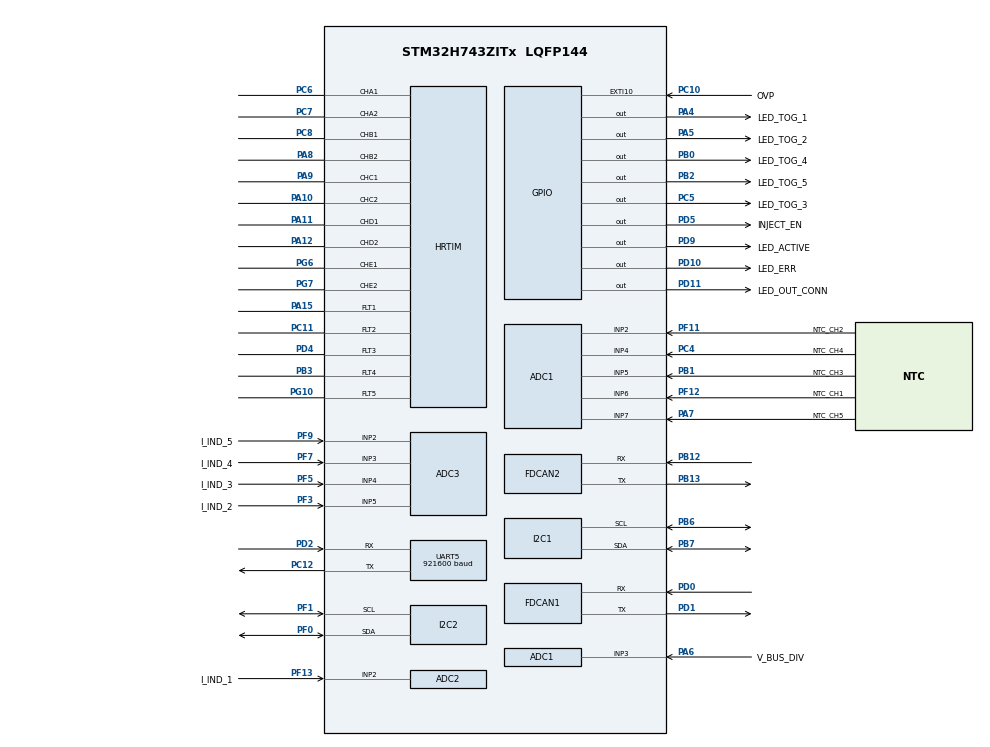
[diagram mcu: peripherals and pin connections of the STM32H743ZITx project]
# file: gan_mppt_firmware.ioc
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ADC1.Channel-0\#ChannelRegularConversion=ADC_CHANNEL_6
ADC1.ClockPrescaler=ADC_CLOCK_ASYNC_DIV4
ADC1.ClockPrescalerADC3=ADC_CLOCK_ASYNC_DIV4
ADC1.NbrOfConversionFlag=1
ADC1.OffsetNumber-0\#ChannelRegularConversion=ADC_OFFSET_NONE
ADC1.OffsetSignedSaturation-0\#ChannelRegularConversion=DISABLE
ADC1.Rank-0\#ChannelRegularConversion=1
ADC1.SamplingTime-0\#ChannelRegularConversion=ADC_SAMPLETIME_1CYCLE_5
ADC1.master=1
ADC2.Channel-0\#ChannelRegularConversion=ADC_CHANNEL_2
ADC2.ClockPrescaler=ADC_CLOCK_ASYNC_DIV4
ADC2.ClockPrescalerADC3=ADC_CLOCK_ASYNC_DIV4
ADC2.ExternalTrigConv=ADC_EXTERNALTRIG_HR1_ADCTRG1
ADC2.NbrOfConversionFlag=1
ADC2.OffsetNumber-0\#ChannelRegularConversion=ADC_OFFSET_NONE
ADC2.OffsetSignedSaturation-0\#ChannelRegularConversion=DISABLE
ADC2.Rank-0\#ChannelRegularConversion=1
ADC2.SamplingTime-0\#ChannelRegularConversion=ADC_SAMPLETIME_1CYCLE_5
ADC3.Channel-0\#ChannelRegularConversion=ADC_CHANNEL_5
ADC3.ClockPrescaler=ADC_CLOCK_ASYNC_DIV4
ADC3.ClockPrescalerADC3=ADC_CLOCK_ASYNC_DIV4
ADC3.ExternalTrigConv=ADC_EXTERNALTRIG_HR1_ADCTRG1
ADC3.NbrOfConversion=1
ADC3.NbrOfConversionFlag=1
ADC3.OffsetNumber-0\#ChannelRegularConversion=ADC_OFFSET_NONE
ADC3.OffsetSignedSaturation-0\#ChannelRegularConversion=DISABLE
ADC3.Rank-0\#ChannelRegularConversion=1
ADC3.SamplingTime-0\#ChannelRegularConversion=ADC_SAMPLETIME_1CYCLE_5
CORTEX_M7.default_mode_Activation=1
FDCAN1.CalculateBaudRateNominal=2500000
FDCAN1.CalculateTimeBitNominal=400
FDCAN1.CalculateTimeQuantumNominal=133.33333333333334
FDCAN2.CalculateBaudRateNominal=2500000
FDCAN2.CalculateTimeBitNominal=400
FDCAN2.CalculateTimeQuantumNominal=133.33333333333334
HRTIM.CompareUnit1-Output_TA1TA2=__NULL
HRTIM.DeadTimeInsertion-Output_TA1TA2=HRTIM_TIMDEADTIMEINSERTION_ENABLED
HRTIM.DeadTimeInsertion-Output_TB1TB2=HRTIM_TIMDEADTIMEINSERTION_ENABLED
HRTIM.DeadTimeInsertion-Output_TC1TC2=HRTIM_TIMDEADTIMEINSERTION_ENABLED
HRTIM.DeadTimeInsertion-Output_TD1TD2=HRTIM_TIMDEADTIMEINSERTION_ENABLED
HRTIM.DeadTimeInsertion-Output_TE1TE2=HRTIM_TIMDEADTIMEINSERTION_ENABLED
HRTIM.Event1-Output_TA1TA2=__NULL
I2C1.Timing=0x307075B1
I2C2.Timing=0x307075B1
Mcu.Family=STM32H7
Mcu.Name=STM32H743ZITx
Mcu.Package=LQFP144
NVIC.EXTI15_10_IRQn=true\:0\:0\:false\:false\:true\:true\:true\:true
NVIC.HRTIM1_FLT_IRQn=true\:0\:0\:false\:false\:true\:true\:true\:true
NVIC.PriorityGroup=NVIC_PRIORITYGROUP_4
PA10.Mode=Output_TC1TC2
PA10.Signal=HRTIM_CHC2
PA11.Mode=Output_TD1TD2
PA11.Signal=HRTIM_CHD1
PA12.Mode=Output_TD1TD2
PA12.Signal=HRTIM_CHD2
PA13\ (JTMS/SWDIO).Mode=Serial_Wire
PA13\ (JTMS/SWDIO).Signal=DEBUG_JTMS-SWDIO
PA14\ (JTCK/SWCLK).Mode=Serial_Wire
PA14\ (JTCK/SWCLK).Signal=DEBUG_JTCK-SWCLK
PA15\ (JTDI).Mode=Fault_Enable1
PA15\ (JTDI).Signal=HRTIM_FLT1
PA4.GPIO_Label=LED_TOG_1
PA4.GPIO_PuPd=GPIO_PULLUP
PA4.Signal=GPIO_Output
PA5.GPIO_Label=LED_TOG_2
PA5.GPIO_PuPd=GPIO_PULLUP
PA5.Signal=GPIO_Output
PA6.GPIO_Label=V_BUS_DIV
PA6.Signal=ADCx_INP3
PA7.GPIO_Label=NTC_CH5
PA7.Signal=ADCx_INP7
PA8.Mode=Output_TB1TB2
PA8.Signal=HRTIM_CHB2
PA9.Mode=Output_TC1TC2
PA9.Signal=HRTIM_CHC1
PB0.GPIO_Label=LED_TOG_4
PB0.GPIO_PuPd=GPIO_PULLUP
PB0.Signal=GPIO_Output
PB1.GPIO_Label=NTC_CH3
PB1.Signal=ADCx_INP5
PB12.Mode=FDCAN_Activate
PB12.Signal=FDCAN2_RX
PB13.Mode=FDCAN_Activate
PB13.Signal=FDCAN2_TX
PB2.GPIO_Label=LED_TOG_5
PB2.GPIO_PuPd=GPIO_PULLUP
PB2.Signal=GPIO_Output
PB3\ (JTDO/TRACESWO).Mode=Fault_Enable4
PB3\ (JTDO/TRACESWO).Signal=HRTIM_FLT4
PB6.Mode=I2C
PB6.Signal=I2C1_SCL
PB7.Mode=I2C
PB7.Signal=I2C1_SDA
PC10.GPIO_Label=OVP
PC10.Signal=GPXTI10
PC11.Mode=Fault_Enable2
PC11.Signal=HRTIM_FLT2
PC12.Mode=Asynchronous
PC12.Signal=UART5_TX
PC4.GPIO_Label=NTC_CH4
PC4.Signal=ADCx_INP4
PC5.GPIO_Label=LED_TOG_3
PC5.GPIO_PuPd=GPIO_PULLUP
PC5.Signal=GPIO_Output
PC6.Mode=Output_TA1TA2
PC6.Signal=HRTIM_CHA1
PC7.Mode=Output_TA1TA2
PC7.Signal=HRTIM_CHA2
PC8.Mode=Output_TB1TB2
PC8.Signal=HRTIM_CHB1
PD0.Mode=FDCAN_Activate
PD0.Signal=FDCAN1_RX
PD1.Mode=FDCAN_Activate
PD1.Signal=FDCAN1_TX
PD10.GPIO_Label=LED_ERR
PD10.Signal=GPIO_Output
PD11.GPIO_Label=LED_OUT_CONN
PD11.Signal=GPIO_Output
PD2.Mode=Asynchronous
PD2.Signal=UART5_RX
PD4.Mode=Fault_Enable3
PD4.Signal=HRTIM_FLT3
PD5.GPIO_Label=INJECT_EN
PD5.Signal=GPIO_Output
PD9.GPIO_Label=LED_ACTIVE
PD9.Signal=GPIO_Output
PF0.Mode=I2C
PF0.Signal=I2C2_SDA
PF1.Mode=I2C
PF1.Signal=I2C2_SCL
PF11.GPIO_Label=NTC_CH2
PF11.Mode=IN2-Single-Ended
PF11.Signal=ADC1_INP2
PF12.GPIO_Label=NTC_CH1
PF12.Mode=IN6-Single-Ended
PF12.Signal=ADC1_INP6
PF13.GPIO_Label=I_IND_1
PF13.Mode=IN2-Single-Ended
PF13.Signal=ADC2_INP2
PF3.GPIO_Label=I_IND_2
PF3.Mode=IN5-Single-Ended
PF3.Signal=ADC3_INP5
PF5.GPIO_Label=I_IND_3
PF5.Mode=IN4-Single-Ended
PF5.Signal=ADC3_INP4
PF7.GPIO_Label=I_IND_4
PF7.Mode=IN3-Single-Ended
PF7.Signal=ADC3_INP3
PF9.GPIO_Label=I_IND_5
PF9.Mode=IN2-Single-Ended
PF9.Signal=ADC3_INP2
PG10.Mode=Fault_Enable5
PG10.Signal=HRTIM_FLT5
PG6.Mode=Output_TE1TE2
PG6.Signal=HRTIM_CHE1
PG7.Mode=Output_TE1TE2
PG7.Signal=HRTIM_CHE2
PH0-OSC_IN\ (PH0).Mode=HSE-External-Oscillator
PH0-OSC_IN\ (PH0).Signal=RCC_OSC_IN
PH1-OSC_OUT\ (PH1).Mode=HSE-External-Oscillator
PH1-OSC_OUT\ (PH1).Signal=RCC_OSC_OUT
ProjectManager.HeapSize=0x200
ProjectManager.StackSize=0x400
ProjectManager.TargetToolchain=CMake
RCC.ADCFreq_Value=76000000
RCC.APB1Freq_Value=120000000
RCC.APB2Freq_Value=120000000
RCC.APB3Freq_Value=120000000
RCC.APB4Freq_Value=120000000
RCC.CortexFreq_Value=480000000
RCC.DIVM1=1
RCC.DIVM2=1
RCC.DIVN1=120
RCC.DIVN2=19
RCC.DIVQ1=8
RCC.HCLKFreq_Value=120000000
RCC.HPRE=RCC_HCLK_DIV4
RCC.HRTIMCLockSelection=RCC_HRTIM1CLK_CPUCLK
RCC.HSE_VALUE=8000000
RCC.PLL2FRACN=0
RCC.PLL3FRACN=0
RCC.PLLFRACN=0
RCC.PLLSourceVirtual=RCC_PLLSOURCE_HSE
RCC.SYSCLKFreq_VALUE=480000000
RCC.SYSCLKSource=RCC_SYSCLKSOURCE_PLLCLK
RCC.USBFreq_Value=120000000
SH.ADCx_INP3.0=ADC1_INP3,IN3-Single-Ended
SH.ADCx_INP4.0=ADC1_INP4,IN4-Single-Ended
SH.ADCx_INP5.0=ADC1_INP5,IN5-Single-Ended
SH.ADCx_INP7.0=ADC1_INP7,IN7-Single-Ended
UART5.BaudRate=921600
VP_MEMORYMAP_VS_MEMORYMAP.Mode=CurAppReg
board=custom

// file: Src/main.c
/* USER CODE BEGIN Header */
/**
  ******************************************************************************
  * @file           : main.c
  * @brief          : Main program body
  ******************************************************************************
  * @attention
  *
  * Copyright (c) 2026 STMicroelectronics.
  * All rights reserved.
  *
  * This software is licensed under terms that can be found in the LICENSE file
  * in the root directory of this software component.
  * If no LICENSE file comes with this software, it is provided AS-IS.
  *
  ******************************************************************************
  */
/* USER CODE END Header */
#include "main.h"
#include "adc.h"
#include "fdcan.h"
#include "hrtim.h"
#include "i2c.h"
#include "usart.h"
#include "gpio.h"

/* USER CODE BEGIN Includes */
#include "app.h"
/* USER CODE END Includes */

void SystemClock_Config(void);
void PeriphCommonClock_Config(void);
static void MPU_Config(void);

int main(void)
{

  /* MPU Configuration--------------------------------------------------------*/
  MPU_Config();

  /* MCU Configuration--------------------------------------------------------*/

  /* Reset of all peripherals, Initializes the Flash interface and the Systick. */
  HAL_Init();

  /* Configure the system clock */
  SystemClock_Config();

  /* Configure the peripherals common clocks */
  PeriphCommonClock_Config();

  /* Initialize all configured peripherals */
  MX_GPIO_Init();
  MX_HRTIM_Init();
  MX_FDCAN1_Init();
  MX_I2C1_Init();
  MX_ADC1_Init();
  MX_FDCAN2_Init();
  MX_I2C2_Init();
  MX_UART5_Init();
  MX_ADC2_Init();
  MX_ADC3_Init();
  /* USER CODE BEGIN 2 */
  app_setup();
  /* USER CODE END 2 */

  /* Infinite loop */
  while (1)
  {

    /* USER CODE BEGIN 3 */
    app_loop();
  }
  /* USER CODE END 3 */
}

void SystemClock_Config(void)
{
  RCC_OscInitTypeDef RCC_OscInitStruct = {0};
  RCC_ClkInitTypeDef RCC_ClkInitStruct = {0};

  /** Supply configuration update enable
  */
  HAL_PWREx_ConfigSupply(PWR_LDO_SUPPLY);

  /** Configure the main internal regulator output voltage
  */
  __HAL_PWR_VOLTAGESCALING_CONFIG(PWR_REGULATOR_VOLTAGE_SCALE0);

  while(!__HAL_PWR_GET_FLAG(PWR_FLAG_VOSRDY)) {}

  /** Initializes the RCC Oscillators according to the specified parameters
  * in the RCC_OscInitTypeDef structure.
  */
  RCC_OscInitStruct.OscillatorType = RCC_OSCILLATORTYPE_HSE;
  RCC_OscInitStruct.HSEState = RCC_HSE_ON;
  RCC_OscInitStruct.PLL.PLLState = RCC_PLL_ON;
  RCC_OscInitStruct.PLL.PLLSource = RCC_PLLSOURCE_HSE;
  RCC_OscInitStruct.PLL.PLLM = 1;
  RCC_OscInitStruct.PLL.PLLN = 120;
  RCC_OscInitStruct.PLL.PLLP = 2;
  RCC_OscInitStruct.PLL.PLLQ = 8;
  RCC_OscInitStruct.PLL.PLLR = 2;
  RCC_OscInitStruct.PLL.PLLRGE = RCC_PLL1VCIRANGE_3;
  RCC_OscInitStruct.PLL.PLLVCOSEL = RCC_PLL1VCOWIDE;
  RCC_OscInitStruct.PLL.PLLFRACN = 0;
  if (HAL_RCC_OscConfig(&RCC_OscInitStruct) != HAL_OK)
  {
    Error_Handler();
  }

  /** Initializes the CPU, AHB and APB buses clocks
  */
  RCC_ClkInitStruct.ClockType = RCC_CLOCKTYPE_HCLK|RCC_CLOCKTYPE_SYSCLK
                              |RCC_CLOCKTYPE_PCLK1|RCC_CLOCKTYPE_PCLK2
                              |RCC_CLOCKTYPE_D3PCLK1|RCC_CLOCKTYPE_D1PCLK1;
  RCC_ClkInitStruct.SYSCLKSource = RCC_SYSCLKSOURCE_PLLCLK;
  RCC_ClkInitStruct.SYSCLKDivider = RCC_SYSCLK_DIV1;
  RCC_ClkInitStruct.AHBCLKDivider = RCC_HCLK_DIV4;
  RCC_ClkInitStruct.APB3CLKDivider = RCC_APB3_DIV1;
  RCC_ClkInitStruct.APB1CLKDivider = RCC_APB1_DIV1;
  RCC_ClkInitStruct.APB2CLKDivider = RCC_APB2_DIV1;
  RCC_ClkInitStruct.APB4CLKDivider = RCC_APB4_DIV1;

  if (HAL_RCC_ClockConfig(&RCC_ClkInitStruct, FLASH_LATENCY_1) != HAL_OK)
  {
    Error_Handler();
  }
}

void PeriphCommonClock_Config(void)
{
  RCC_PeriphCLKInitTypeDef PeriphClkInitStruct = {0};

  /** Initializes the peripherals clock
  */
  PeriphClkInitStruct.PeriphClockSelection = RCC_PERIPHCLK_ADC;
  PeriphClkInitStruct.PLL2.PLL2M = 1;
  PeriphClkInitStruct.PLL2.PLL2N = 19;
  PeriphClkInitStruct.PLL2.PLL2P = 2;
  PeriphClkInitStruct.PLL2.PLL2Q = 2;
  PeriphClkInitStruct.PLL2.PLL2R = 2;
  PeriphClkInitStruct.PLL2.PLL2RGE = RCC_PLL2VCIRANGE_3;
  PeriphClkInitStruct.PLL2.PLL2VCOSEL = RCC_PLL2VCOMEDIUM;
  PeriphClkInitStruct.PLL2.PLL2FRACN = 0;
  PeriphClkInitStruct.AdcClockSelection = RCC_ADCCLKSOURCE_PLL2;
  if (HAL_RCCEx_PeriphCLKConfig(&PeriphClkInitStruct) != HAL_OK)
  {
    Error_Handler();
  }
}

 /* MPU Configuration */

void MPU_Config(void)
{
  MPU_Region_InitTypeDef MPU_InitStruct = {0};

  /* Disables the MPU */
  HAL_MPU_Disable();

  /** Initializes and configures the Region and the memory to be protected
  */
  MPU_InitStruct.Enable = MPU_REGION_ENABLE;
  MPU_InitStruct.Number = MPU_REGION_NUMBER0;
  MPU_InitStruct.BaseAddress = 0x0;
  MPU_InitStruct.Size = MPU_REGION_SIZE_4GB;
  MPU_InitStruct.SubRegionDisable = 0x87;
  MPU_InitStruct.TypeExtField = MPU_TEX_LEVEL0;
  MPU_InitStruct.AccessPermission = MPU_REGION_NO_ACCESS;
  MPU_InitStruct.DisableExec = MPU_INSTRUCTION_ACCESS_DISABLE;
  MPU_InitStruct.IsShareable = MPU_ACCESS_SHAREABLE;
  MPU_InitStruct.IsCacheable = MPU_ACCESS_NOT_CACHEABLE;
  MPU_InitStruct.IsBufferable = MPU_ACCESS_NOT_BUFFERABLE;

  HAL_MPU_ConfigRegion(&MPU_InitStruct);
  /* Enables the MPU */
  HAL_MPU_Enable(MPU_PRIVILEGED_DEFAULT);

}

void Error_Handler(void)
{
  __disable_irq();
  while (1)
  {
  }
}
